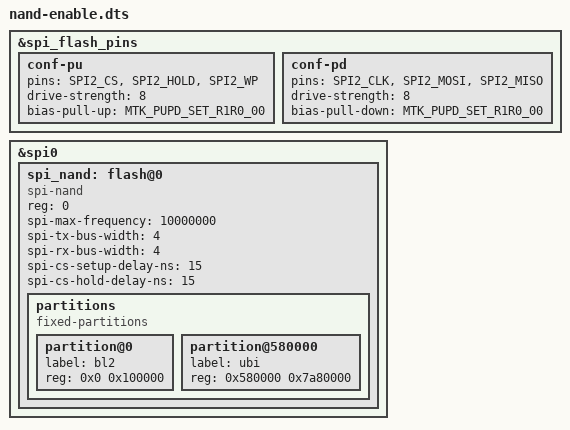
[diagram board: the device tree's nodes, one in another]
/dts-v1/;
/plugin/;

#define MTK_PUPD_SET_R1R0_00 100

&spi_flash_pins {
    conf-pu {
      pins = "SPI2_CS", "SPI2_HOLD", "SPI2_WP";
      drive-strength = <8>;
      bias-pull-up = <MTK_PUPD_SET_R1R0_00>;
    };

    conf-pd {
      pins = "SPI2_CLK", "SPI2_MOSI", "SPI2_MISO";
      drive-strength = <8>;
      bias-pull-down = <MTK_PUPD_SET_R1R0_00>;
    };
};

&spi0 {
  #address-cells = <1>;
  #size-cells = <0>;

  spi_nand: flash@0 {
    compatible = "spi-nand";
    reg = <0>;
    spi-max-frequency = <10000000>;
    spi-tx-bus-width = <4>;
    spi-rx-bus-width = <4>;
    spi-cs-setup-delay-ns = <15>;
    spi-cs-hold-delay-ns = <15>;

    partitions {
      compatible = "fixed-partitions";
      #address-cells = <1>;
      #size-cells = <1>;

      partition@0 {
        label = "bl2";
        reg = <0x0 0x100000>;
//      read-only;
      };

      partition@580000 {
        label = "ubi";
        reg = <0x580000 0x7a80000>;
      };
    };
  };
};
